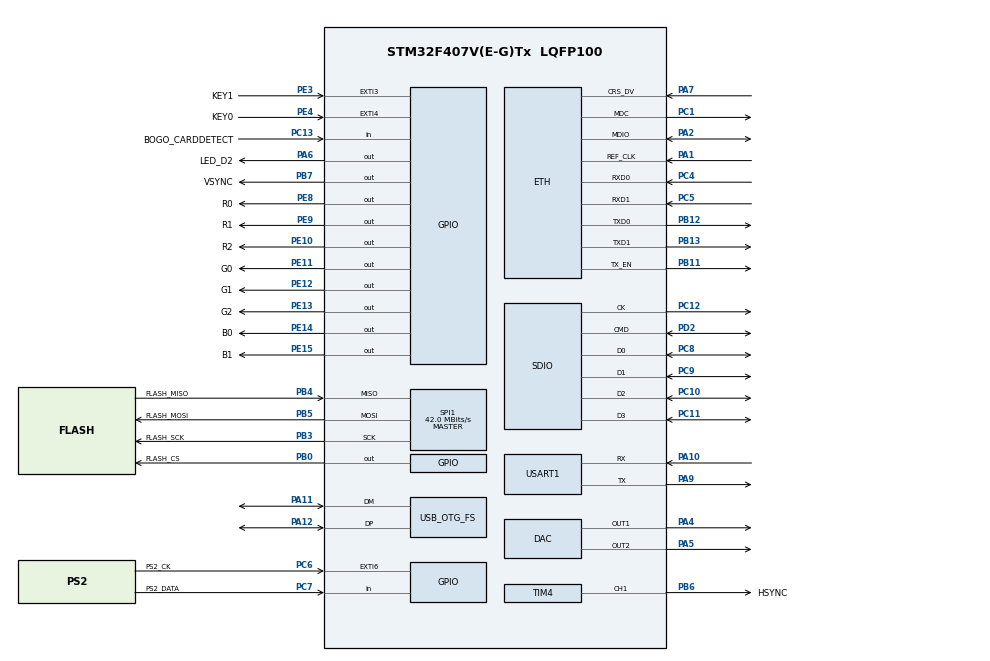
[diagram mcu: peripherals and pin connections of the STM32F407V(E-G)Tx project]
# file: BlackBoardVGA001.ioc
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DAC.DAC_OutputBuffer=DAC_OUTPUTBUFFER_DISABLE
DAC.DAC_OutputBuffer2=DAC_OUTPUTBUFFER_DISABLE
Dma.DAC1.2.Direction=DMA_MEMORY_TO_PERIPH
Dma.DAC1.2.FIFOMode=DMA_FIFOMODE_DISABLE
Dma.DAC1.2.Instance=DMA1_Stream5
Dma.DAC1.2.MemDataAlignment=DMA_MDATAALIGN_HALFWORD
Dma.DAC1.2.MemInc=DMA_MINC_ENABLE
Dma.DAC1.2.Mode=DMA_NORMAL
Dma.DAC1.2.PeriphDataAlignment=DMA_PDATAALIGN_HALFWORD
Dma.DAC1.2.PeriphInc=DMA_PINC_DISABLE
Dma.DAC1.2.Priority=DMA_PRIORITY_LOW
Dma.DAC2.3.Direction=DMA_MEMORY_TO_PERIPH
Dma.DAC2.3.FIFOMode=DMA_FIFOMODE_DISABLE
Dma.DAC2.3.Instance=DMA1_Stream6
Dma.DAC2.3.MemDataAlignment=DMA_MDATAALIGN_HALFWORD
Dma.DAC2.3.MemInc=DMA_MINC_ENABLE
Dma.DAC2.3.Mode=DMA_NORMAL
Dma.DAC2.3.PeriphDataAlignment=DMA_PDATAALIGN_HALFWORD
Dma.DAC2.3.PeriphInc=DMA_PINC_DISABLE
Dma.DAC2.3.Priority=DMA_PRIORITY_LOW
Dma.Request0=SDIO_RX
Dma.Request1=SDIO_TX
Dma.Request2=DAC1
Dma.Request3=DAC2
Dma.Request4=TIM1_UP
Dma.SDIO_RX.0.Direction=DMA_PERIPH_TO_MEMORY
Dma.SDIO_RX.0.FIFOMode=DMA_FIFOMODE_ENABLE
Dma.SDIO_RX.0.FIFOThreshold=DMA_FIFO_THRESHOLD_FULL
Dma.SDIO_RX.0.Instance=DMA2_Stream6
Dma.SDIO_RX.0.MemBurst=DMA_MBURST_INC4
Dma.SDIO_RX.0.MemDataAlignment=DMA_MDATAALIGN_WORD
Dma.SDIO_RX.0.MemInc=DMA_MINC_ENABLE
Dma.SDIO_RX.0.Mode=DMA_PFCTRL
Dma.SDIO_RX.0.PeriphBurst=DMA_PBURST_INC4
Dma.SDIO_RX.0.PeriphDataAlignment=DMA_PDATAALIGN_WORD
Dma.SDIO_RX.0.PeriphInc=DMA_PINC_DISABLE
Dma.SDIO_RX.0.Priority=DMA_PRIORITY_LOW
Dma.SDIO_TX.1.Direction=DMA_MEMORY_TO_PERIPH
Dma.SDIO_TX.1.FIFOMode=DMA_FIFOMODE_ENABLE
Dma.SDIO_TX.1.FIFOThreshold=DMA_FIFO_THRESHOLD_FULL
Dma.SDIO_TX.1.Instance=DMA2_Stream3
Dma.SDIO_TX.1.MemBurst=DMA_MBURST_INC4
Dma.SDIO_TX.1.MemDataAlignment=DMA_MDATAALIGN_WORD
Dma.SDIO_TX.1.MemInc=DMA_MINC_ENABLE
Dma.SDIO_TX.1.Mode=DMA_PFCTRL
Dma.SDIO_TX.1.PeriphBurst=DMA_PBURST_INC4
Dma.SDIO_TX.1.PeriphDataAlignment=DMA_PDATAALIGN_WORD
Dma.SDIO_TX.1.PeriphInc=DMA_PINC_DISABLE
Dma.SDIO_TX.1.Priority=DMA_PRIORITY_LOW
Dma.TIM1_UP.4.Direction=DMA_MEMORY_TO_PERIPH
Dma.TIM1_UP.4.FIFOMode=DMA_FIFOMODE_ENABLE
Dma.TIM1_UP.4.FIFOThreshold=DMA_FIFO_THRESHOLD_FULL
Dma.TIM1_UP.4.Instance=DMA2_Stream5
Dma.TIM1_UP.4.MemBurst=DMA_MBURST_SINGLE
Dma.TIM1_UP.4.MemDataAlignment=DMA_MDATAALIGN_WORD
Dma.TIM1_UP.4.MemInc=DMA_MINC_ENABLE
Dma.TIM1_UP.4.Mode=DMA_NORMAL
Dma.TIM1_UP.4.PeriphBurst=DMA_PBURST_SINGLE
Dma.TIM1_UP.4.PeriphDataAlignment=DMA_PDATAALIGN_BYTE
Dma.TIM1_UP.4.PeriphInc=DMA_PINC_DISABLE
Dma.TIM1_UP.4.Priority=DMA_PRIORITY_VERY_HIGH
ETH.MediaInterface=ETH_MEDIA_INTERFACE_RMII
FATFS.BSP.number=1
FATFS0.BSP.STBoard=false
FATFS0.BSP.api=Unknown
FATFS0.BSP.i2caddr=0
FATFS0.BSP.instance=PC13-ANTI_TAMP
FATFS0.BSP.ip=GPIO
FATFS0.BSP.mode=Input
FATFS0.BSP.name=Detect_SDIO
FATFS0.BSP.solution=PC13-ANTI_TAMP
FREERTOS.INCLUDE_uxTaskGetStackHighWaterMark=1
FREERTOS.INCLUDE_uxTaskGetStackHighWaterMark2=1
FREERTOS.INCLUDE_xTaskGetHandle=1
FREERTOS.Tasks01=defaultTask,0,128,StartDefaultTask,Default,NULL,Static,defaultTaskBuffer,defaultTaskControlBlock
FREERTOS.configCHECK_FOR_STACK_OVERFLOW=2
FREERTOS.configENABLE_FPU=1
FREERTOS.configTOTAL_HEAP_SIZE=16384
FREERTOS.configUSE_MALLOC_FAILED_HOOK=1
FREERTOS.configUSE_NEWLIB_REENTRANT=1
FREERTOS.configUSE_TRACE_FACILITY=1
FREERTOS.copyHeapFile=0
LWIP.LWIP_DNS=1
LWIP.Version=v2.1.2_Cube
Mcu.Family=STM32F4
Mcu.Name=STM32F407V(E-G)Tx
Mcu.Package=LQFP100
NVIC.DMA1_Stream5_IRQn=true\:5\:0\:false\:false\:true\:true\:false\:true
NVIC.DMA1_Stream6_IRQn=true\:5\:0\:false\:false\:true\:true\:false\:true
NVIC.DMA2_Stream3_IRQn=true\:5\:0\:false\:false\:true\:true\:false\:true
NVIC.DMA2_Stream5_IRQn=true\:5\:0\:false\:false\:true\:true\:false\:true
NVIC.DMA2_Stream6_IRQn=true\:5\:0\:false\:false\:true\:true\:false\:true
NVIC.ETH_IRQn=true\:5\:0\:false\:false\:true\:true\:false\:true
NVIC.EXTI3_IRQn=true\:5\:0\:false\:false\:true\:true\:true\:true
NVIC.EXTI4_IRQn=true\:5\:0\:false\:false\:true\:true\:true\:true
NVIC.EXTI9_5_IRQn=true\:5\:0\:false\:false\:true\:true\:true\:true
NVIC.FLASH_IRQn=true\:5\:0\:false\:false\:true\:true\:true\:true
NVIC.OTG_FS_IRQn=true\:5\:0\:false\:false\:true\:true\:false\:true
NVIC.PriorityGroup=NVIC_PRIORITYGROUP_4
NVIC.SDIO_IRQn=true\:5\:0\:false\:false\:true\:true\:true\:true
NVIC.SPI1_IRQn=true\:5\:0\:false\:false\:true\:true\:true\:true
NVIC.TIM4_IRQn=true\:0\:0\:true\:false\:true\:false\:true\:true
NVIC.TIM6_DAC_IRQn=true\:5\:0\:false\:false\:true\:true\:true\:true
NVIC.TIM8_BRK_TIM12_IRQn=true\:0\:0\:false\:false\:true\:false\:false\:true
NVIC.TimeBase=TIM8_BRK_TIM12_IRQn
NVIC.TimeBaseIP=TIM12
NVIC.USART1_IRQn=true\:5\:0\:false\:false\:true\:true\:true\:true
PA0-WKUP.Mode=SYS_WakeUp0
PA0-WKUP.Signal=SYS_WKUP
PA1.Mode=RMII
PA1.Signal=ETH_REF_CLK
PA10.Mode=Asynchronous
PA10.Signal=USART1_RX
PA11.Mode=Device_Only
PA11.Signal=USB_OTG_FS_DM
PA12.Mode=Device_Only
PA12.Signal=USB_OTG_FS_DP
PA13.Mode=Serial_Wire
PA13.Signal=SYS_JTMS-SWDIO
PA14.Mode=Serial_Wire
PA14.Signal=SYS_JTCK-SWCLK
PA2.Mode=RMII
PA2.Signal=ETH_MDIO
PA4.Signal=COMP_DAC1_group
PA5.Signal=COMP_DAC2_group
PA6.GPIO_Label=LED_D2
PA6.GPIO_ModeDefaultOutputPP=GPIO_MODE_OUTPUT_OD
PA6.PinState=GPIO_PIN_SET
PA6.Signal=GPIO_Output
PA7.Mode=RMII
PA7.Signal=ETH_CRS_DV
PA9.Mode=Asynchronous
PA9.Signal=USART1_TX
PB0.GPIO_Label=FLASH_CS
PB0.GPIO_Speed=GPIO_SPEED_FREQ_VERY_HIGH
PB0.PinState=GPIO_PIN_SET
PB0.Signal=GPIO_Output
PB11.Mode=RMII
PB11.Signal=ETH_TX_EN
PB12.Mode=RMII
PB12.Signal=ETH_TXD0
PB13.Mode=RMII
PB13.Signal=ETH_TXD1
PB3.GPIO_Label=FLASH_SCK
PB3.Mode=Full_Duplex_Master
PB3.Signal=SPI1_SCK
PB4.GPIO_Label=FLASH_MISO
PB4.Mode=Full_Duplex_Master
PB4.Signal=SPI1_MISO
PB5.GPIO_Label=FLASH_MOSI
PB5.Mode=Full_Duplex_Master
PB5.Signal=SPI1_MOSI
PB6.GPIO_Label=HSYNC
PB6.GPIO_Speed=GPIO_SPEED_FREQ_HIGH
PB6.Signal=S_TIM4_CH1
PB7.GPIO_Label=VSYNC
PB7.GPIO_Speed=GPIO_SPEED_FREQ_HIGH
PB7.Signal=GPIO_Output
PC1.Mode=RMII
PC1.Signal=ETH_MDC
PC10.GPIO_PuPd=GPIO_NOPULL
PC10.Mode=SD_4_bits_Wide_bus
PC10.Signal=SDIO_D2
PC11.GPIO_PuPd=GPIO_NOPULL
PC11.Mode=SD_4_bits_Wide_bus
PC11.Signal=SDIO_D3
PC12.Mode=SD_4_bits_Wide_bus
PC12.Signal=SDIO_CK
PC13-ANTI_TAMP.GPIO_Label=BOGO_CARDDETECT
PC13-ANTI_TAMP.GPIO_PuPd=GPIO_PULLDOWN
PC13-ANTI_TAMP.Signal=GPIO_Input
PC14-OSC32_IN.Mode=LSE-External-Oscillator
PC14-OSC32_IN.Signal=RCC_OSC32_IN
PC15-OSC32_OUT.Mode=LSE-External-Oscillator
PC15-OSC32_OUT.Signal=RCC_OSC32_OUT
PC4.Mode=RMII
PC4.Signal=ETH_RXD0
PC5.Mode=RMII
PC5.Signal=ETH_RXD1
PC6.GPIO_Label=PS2_CK
PC6.GPIO_ModeDefaultEXTI=GPIO_MODE_IT_FALLING
PC6.GPIO_PuPd=GPIO_PULLUP
PC6.Signal=GPXTI6
PC7.GPIO_Label=PS2_DATA
PC7.GPIO_PuPd=GPIO_PULLUP
PC7.Signal=GPIO_Input
PC8.GPIO_PuPd=GPIO_NOPULL
PC8.Mode=SD_4_bits_Wide_bus
PC8.Signal=SDIO_D0
PC9.GPIO_PuPd=GPIO_NOPULL
PC9.Mode=SD_4_bits_Wide_bus
PC9.Signal=SDIO_D1
PD2.GPIO_PuPd=GPIO_NOPULL
PD2.Mode=SD_4_bits_Wide_bus
PD2.Signal=SDIO_CMD
PE10.GPIO_Label=R2
PE10.GPIO_Speed=GPIO_SPEED_FREQ_VERY_HIGH
PE10.Signal=GPIO_Output
PE11.GPIO_Label=G0
PE11.GPIO_Speed=GPIO_SPEED_FREQ_VERY_HIGH
PE11.Signal=GPIO_Output
PE12.GPIO_Label=G1
PE12.GPIO_Speed=GPIO_SPEED_FREQ_VERY_HIGH
PE12.Signal=GPIO_Output
PE13.GPIO_Label=G2
PE13.GPIO_Speed=GPIO_SPEED_FREQ_VERY_HIGH
PE13.Signal=GPIO_Output
PE14.GPIO_Label=B0
PE14.GPIO_Speed=GPIO_SPEED_FREQ_VERY_HIGH
PE14.Signal=GPIO_Output
PE15.GPIO_Label=B1
PE15.GPIO_Speed=GPIO_SPEED_FREQ_VERY_HIGH
PE15.Signal=GPIO_Output
PE3.GPIO_Label=KEY1
PE3.GPIO_ModeDefaultEXTI=GPIO_MODE_IT_RISING_FALLING
PE3.GPIO_PuPd=GPIO_PULLUP
PE3.Signal=GPXTI3
PE4.GPIO_Label=KEY0
PE4.GPIO_ModeDefaultEXTI=GPIO_MODE_IT_RISING_FALLING
PE4.GPIO_PuPd=GPIO_PULLUP
PE4.Signal=GPXTI4
PE8.GPIO_Label=R0
PE8.GPIO_Speed=GPIO_SPEED_FREQ_VERY_HIGH
PE8.Signal=GPIO_Output
PE9.GPIO_Label=R1
PE9.GPIO_Speed=GPIO_SPEED_FREQ_VERY_HIGH
PE9.Signal=GPIO_Output
PH0-OSC_IN.Mode=HSE-External-Oscillator
PH0-OSC_IN.Signal=RCC_OSC_IN
PH1-OSC_OUT.Mode=HSE-External-Oscillator
PH1-OSC_OUT.Signal=RCC_OSC_OUT
ProjectManager.HeapSize=0x200
ProjectManager.StackSize=0x400
ProjectManager.TargetToolchain=SW4STM32
RCC.48MHZClocksFreq_Value=48000000
RCC.AHBFreq_Value=168000000
RCC.APB1CLKDivider=RCC_HCLK_DIV4
RCC.APB1Freq_Value=42000000
RCC.APB1TimFreq_Value=84000000
RCC.APB2CLKDivider=RCC_HCLK_DIV2
RCC.APB2Freq_Value=84000000
RCC.APB2TimFreq_Value=168000000
RCC.CortexFreq_Value=168000000
RCC.HCLKFreq_Value=168000000
RCC.HSE_VALUE=8000000
RCC.HSI_VALUE=16000000
RCC.PLLM=4
RCC.PLLN=168
RCC.PLLQ=7
RCC.RCC_RTC_Clock_Source=RCC_RTCCLKSOURCE_LSE
RCC.RCC_RTC_Clock_SourceVirtual=RCC_RTCCLKSOURCE_LSE
RCC.SYSCLKFreq_VALUE=168000000
RCC.SYSCLKSource=RCC_SYSCLKSOURCE_PLLCLK
RCC.VCOOutputFreq_Value=336000000
RTC.Date=1
RTC.Month=RTC_MONTH_JUNE
RTC.WeekDay=RTC_WEEKDAY_MONDAY
RTC.Year=20
SDIO.ClockBypass=SDIO_CLOCK_BYPASS_DISABLE
SDIO.ClockDiv=0
SH.COMP_DAC1_group.0=DAC_OUT1,DAC_OUT1
SH.COMP_DAC2_group.0=DAC_OUT2,DAC_OUT2
SH.S_TIM4_CH1.0=TIM4_CH1,PWM Generation1 CH1
SPI1.CalculateBaudRate=42.0 MBits/s
SPI1.Direction=SPI_DIRECTION_2LINES
SPI1.Mode=SPI_MODE_MASTER
SPI1.VirtualType=VM_MASTER
TIM1.Channel-PWM\ Generation1\ No\ Output=TIM_CHANNEL_1
TIM1.OCPolarity_1=TIM_OCPOLARITY_HIGH
TIM1.Period=3
TIM1.Pulse-PWM\ Generation1\ No\ Output=2
TIM4.Channel-Output\ Compare2\ No\ Output=TIM_CHANNEL_2
TIM4.Channel-Output\ Compare3\ No\ Output=TIM_CHANNEL_3
TIM4.Channel-PWM\ Generation1\ CH1=TIM_CHANNEL_1
TIM4.OC1Preload_PWM=DISABLE
TIM4.OCMode_2=TIM_OCMODE_ACTIVE
TIM4.OCPolarity_1=TIM_OCPOLARITY_HIGH
TIM4.Period=1055
TIM4.Prescaler=1
TIM4.Pulse-Output\ Compare2\ No\ Output=216
TIM4.Pulse-Output\ Compare3\ No\ Output=1016
TIM4.Pulse-PWM\ Generation1\ CH1=128
TIM4.TIM_MasterOutputTrigger=TIM_TRGO_OC2REF
TIM4.TIM_MasterSlaveMode=TIM_MASTERSLAVEMODE_DISABLE
USART1.VirtualMode=VM_ASYNC
USB_DEVICE.CLASS_NAME_FS=CDC
USB_DEVICE.VirtualMode-CDC_FS=Cdc
USB_DEVICE.VirtualModeFS=Cdc_FS
USB_OTG_FS.VirtualMode=Device_Only
VP_FATFS_VS_SDIO.Mode=SDIO
VP_FREERTOS_VS_CMSIS_V1.Mode=CMSIS_V1
VP_LWIP_VS_Enabled.Mode=Enabled
VP_RTC_VS_RTC_Activate.Mode=RTC_Enabled
VP_RTC_VS_RTC_Calendar.Mode=RTC_Calendar
VP_SYS_VS_tim12.Mode=TIM12
VP_TIM1_VS_ClockSourceINT.Mode=Internal
VP_TIM1_VS_ClockSourceITR.Mode=TriggerSource_ITR3
VP_TIM1_VS_ControllerModeTrigger.Mode=Trigger Mode
VP_TIM1_VS_no_output1.Mode=PWM Generation1 No Output
VP_TIM4_VS_ClockSourceINT.Mode=Internal
VP_TIM4_VS_no_output2.Mode=Output Compare2 No Output
VP_TIM4_VS_no_output3.Mode=Output Compare3 No Output
VP_USB_DEVICE_VS_USB_DEVICE_CDC_FS.Mode=CDC_FS
board=custom

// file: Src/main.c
/* USER CODE BEGIN Header */
/**
  ******************************************************************************
  * @file           : main.c
  * @brief          : Main program body
  ******************************************************************************
  * @attention
  *
  * <h2><center>&copy; Copyright (c) 2020 STMicroelectronics.
  * All rights reserved.</center></h2>
  *
  * This software component is licensed by ST under BSD 3-Clause license,
  * the "License"; You may not use this file except in compliance with the
  * License. You may obtain a copy of the License at:
  *                        opensource.org/licenses/BSD-3-Clause
  *
  ******************************************************************************
  */
/* USER CODE END Header */

#include "main.h"
#include "cmsis_os.h"
#include "fatfs.h"
#include "lwip.h"
#include "usb_device.h"

/* USER CODE BEGIN Includes */

#if HAVE_USBCDC
#include "usbd_cdc.h"	//just for the XXX_USBCDC_PresenceHack()
#endif
#include "system_interfaces.h"
#include "serial_devices.h"
#include "util_circbuff2.h"

#include "lamps.h"
#include "task_notification_bits.h"

#include "task_monitor.h"

#include "video.h"

//get the debug cycle counter as a high-resolution clock
uint32_t inline getCyCnt() { return DWT->CYCCNT; }

#ifndef COUNTOF
#define COUNTOF(arr) (sizeof(arr)/sizeof(arr[0]))
#endif

#if ! HAVE_UART1 && ! HAVE_USBCDC
#error You must set at least one of HAVE_UART1 HAVE_USBCDC to 1 in project settings
#endif

//This controls whether we use the FreeRTOS heap implementation to also provide
//the libc malloc() and friends.
#define USE_FREERTOS_HEAP_IMPL 1

//resource usage statistics collected in default task for production tuning
#ifdef DEBUG
volatile size_t g_nHeapFree;
volatile size_t g_nMinEverHeapFree;
#if HAVE_UART1
volatile int g_nMaxUART1TxQueue;
volatile int g_nMaxUART1RxQueue;
#endif
#if HAVE_USBCDC
volatile int g_nMaxCDCTxQueue;
volatile int g_nMaxCDCRxQueue;
#endif
volatile int g_nMinStackFreeDefault;
volatile int g_nMinStackFreeMonitor;

//alas, the LWIP and ETH discard the thread id's they create
//\Middlewares\Third_Party\LwIP\src\api\tcpip.c:617
//\src\ethernetif.c:273 (this one is in a USER block, so we can edit)
//we will use carnal knowledge of their thread names, and the xTaskGetHandle api
TaskHandle_t g_thTCP;
TaskHandle_t g_thETH;
volatile int g_nMinStackFreeTCP;
volatile int g_nMinStackFreeETH;

//XXX others
#endif

#if USE_FREERTOS_HEAP_IMPL

#if configAPPLICATION_ALLOCATED_HEAP
//we define our heap (to be used by FreeRTOS heap_4.c implementation) to be
//exactly where we want it to be.
__attribute__((aligned(8)))
uint8_t ucHeap[ configTOTAL_HEAP_SIZE ];
#endif
//we implemented a 'realloc' for a heap_4 derived implementation
extern void* pvPortRealloc( void* pvOrig, size_t xWantedSize );
//we implemented a 'heapwalk' function
typedef int (*CBK_HEAPWALK) ( void* pblk, uint32_t nBlkSize, int bIsFree, void* pinst );
extern int vPortHeapWalk ( CBK_HEAPWALK pfnWalk, void* pinst );

//'wrapped functions' for library interpositioning
//you must specify these gcc (linker-directed) options to cause the wrappers'
//delights to be generated:

// -Wl,--wrap,malloc -Wl,--wrap,free -Wl,--wrap,realloc -Wl,--wrap,calloc -Wl,--wrap,_malloc_r -Wl,--wrap,_free_r -Wl,--wrap,_realloc_r -Wl,--wrap,_calloc_r

//hmm; can I declare these 'inline' and save a little code and stack?
void* __wrap_malloc ( size_t size ) { return pvPortMalloc ( size ); }
void __wrap_free ( void* pv ) { vPortFree ( pv ); }
void* __wrap_realloc ( void* pv, size_t size ) { return pvPortRealloc ( pv, size ); }

void* __wrap__malloc_r ( struct _reent* r, size_t size ) { return pvPortMalloc ( size ); }
void __wrap__free_r ( struct _reent* r, void* pv ) { vPortFree ( pv ); }
void* __wrap__realloc_r ( struct _reent* r, void* pv, size_t size ) { return pvPortRealloc ( pv, size ); }

#endif

/* USER CODE END Includes */

/* USER CODE BEGIN PM */

//I wanted the task stuff (especially FreeRTOS stack) to be in CCM, freeing the
//main memory for things that might need to interact with peripherals;
//especially DMA.

//The other stuff doesn't /have/ to be there, but might as well get it out of
//main SRAM since the CCRAM is otherwise going unused.

//XXX generated code hack; we put things right where we want them to be, above.
//If you get some linker errors after you modify the CubeMX project, it might
//be that it added stuff during generation, below, and that is conditioned-out.
//So just copy whatever it is above.
#if 1

//DMA 'handles' cannot be in CCM because the DMA controller will access some members and CCM is inaccessible to the DMA controllers.
SD_HandleTypeDef hsd;// __ccram;
DMA_HandleTypeDef hdma_sdio_rx;// __ccram;
DMA_HandleTypeDef hdma_sdio_tx;// __ccram;

osThreadId defaultTaskHandle __ccram;
uint32_t defaultTaskBuffer[ 128 ] __ccram;
osStaticThreadDef_t defaultTaskControlBlock __ccram;

#else
/* USER CODE END PM */

SD_HandleTypeDef hsd;
DMA_HandleTypeDef hdma_sdio_rx;
DMA_HandleTypeDef hdma_sdio_tx;

osThreadId defaultTaskHandle;
uint32_t defaultTaskBuffer[ 128 ];
osStaticThreadDef_t defaultTaskControlBlock;
/* USER CODE BEGIN PV */
//XXX end generate code hack
#endif

/* USER CODE END PV */

void SystemClock_Config(void);
static void MX_GPIO_Init(void);
static void MX_DMA_Init(void);
static void MX_RTC_Init(void);
static void MX_SDIO_SD_Init(void);
static void MX_SPI1_Init(void);
static void MX_USART1_UART_Init(void);
static void MX_DAC_Init(void);
static void MX_TIM4_Init(void);
static void MX_TIM1_Init(void);
void StartDefaultTask(void const * argument);

/* USER CODE BEGIN 0 */

//hack:  the CubeMX generated LL code for SystemClock_Config /always/ resets
//the backup domain, thereby clearing the RTC amongst other things.  It is not
//easy to fix because there are no USER tags therein, we we neutralize those
//APIs altogether.
#define LL_RCC_ForceBackupDomainReset(a)do{}while(0)
#define LL_RCC_ReleaseBackupDomainReset(a)do{}while(0)

/* USER CODE END 0 */

int main(void)
{
  /* USER CODE BEGIN 1 */
	//enable the core debug cycle counter to be used as a precision timer
	CoreDebug->DEMCR |= CoreDebug_DEMCR_TRCENA_Msk;
	DWT->CYCCNT = 0;
	DWT->CTRL |= DWT_CTRL_CYCCNTENA_Msk;

	//set up that the video-related timers will stop when debugging
	__HAL_DBGMCU_FREEZE_TIM4();
	__HAL_DBGMCU_FREEZE_TIM1();

	//do a dummy alloc to cause the heap to be init'ed and so the memory stats as well
	vPortFree ( pvPortMalloc ( 0 ) );

  /* USER CODE END 1 */

  /* MCU Configuration--------------------------------------------------------*/

  /* Reset of all peripherals, Initializes the Flash interface and the Systick. */
  HAL_Init();

  /* USER CODE BEGIN Init */

#if HAVE_USBCDC
	//if you get a linker fail on the following, it is because some manual
	//changes to:
	//  .\Middlewares\ST\STM32_USB_Device_Library\Class\CDC\Inc\usbd_cdc.h
	//  .\Middlewares\ST\STM32_USB_Device_Library\Class\CDC\Src\usbd_cdc.c
	//  .\Src\usbd_cdc_if.c
	//must be applied.  There are backups of those files to help with that.
	//This has to be done manually, because the changes are in tool generated
	//code that gets overwritten when you re-run STM32CubeMX.  The nature of
	//those changes are such that when they are overwritten, you will still
	//be able to build but stuff won't work at runtime.  This hack will cause
	//the build to fail if you forget to merge those changes back on, thus
	//prompting you to do so.
	//There is a #fixups/fixup.bat to help with this.
	//Sorry for the inconvenience, but I don't think there is any better way
	//of making it obvious that this chore simply must be done.
	XXX_USBCDC_PresenceHack();	//this does nothing real; do not delete
#endif

	//if there are any __ccram objects that need static initialization, you'll
	//need to do that here because the startup code does not init them out-of-
	//box like it does with the .data section (alternatively, you can modify
	//the startup_stm32f407xx.s to do this, along with some linker script
	//shenanigans to set up the needed symbols).
	defaultTaskHandle = NULL;
	g_thMonitor = NULL;
	g_pMonitorIOIf = NULL;

  /* USER CODE END Init */

  /* Configure the system clock */
  SystemClock_Config();

  /* USER CODE BEGIN SysInit */

	//turn on the low power regulator so the backup sram will indeed be battery backed
	LL_PWR_EnableBkUpAccess();	//ensure access to the backup domain, if not already

	{	//ensure the power clock is on, if not already
	SET_BIT(RCC->APB1ENR, RCC_APB1ENR_PWREN);
	volatile uint32_t n = READ_BIT(RCC->APB1ENR, RCC_APB1ENR_PWREN);	//Delay after an RCC peripheral clock enabling
	(void)n;
	}

	LL_PWR_EnableBkUpRegulator();	//turn on the backup regulator...
	while ( !LL_PWR_IsActiveFlag_BRR() ) {}	//... and wait for stabilization XXX timeout?
	//leave access to the backup domain active so we can freely fiddle with rtc, etc

	{	//enable the backup sram clock, and just leave it running so we can access freely
	SET_BIT(RCC->AHB1ENR, RCC_AHB1ENR_BKPSRAMEN);
	volatile uint32_t n = READ_BIT(RCC->AHB1ENR, RCC_AHB1ENR_BKPSRAMEN);	//Delay after an RCC peripheral clock enabling
	(void)n;
	}

  /* USER CODE END SysInit */

  /* Initialize all configured peripherals */
  MX_GPIO_Init();
  MX_DMA_Init();
  MX_RTC_Init();
  MX_SDIO_SD_Init();
  MX_SPI1_Init();
  MX_USART1_UART_Init();
  MX_FATFS_Init();
  MX_DAC_Init();
  MX_TIM4_Init();
  MX_TIM1_Init();

  /* Create the thread(s) */
  /* definition and creation of defaultTask */
  osThreadStaticDef(defaultTask, StartDefaultTask, osPriorityNormal, 0, 128, defaultTaskBuffer, &defaultTaskControlBlock);
  defaultTaskHandle = osThreadCreate(osThread(defaultTask), NULL);

  /* Start scheduler */
  osKernelStart();

  /* We should never get here as control is now taken by the scheduler */
  /* Infinite loop */
  while (1)
  {

  }
}

void SystemClock_Config(void)
{
  LL_FLASH_SetLatency(LL_FLASH_LATENCY_5);

  if(LL_FLASH_GetLatency() != LL_FLASH_LATENCY_5)
  {
  Error_Handler();
  }
  LL_PWR_SetRegulVoltageScaling(LL_PWR_REGU_VOLTAGE_SCALE1);
  LL_RCC_HSE_Enable();

   /* Wait till HSE is ready */
  while(LL_RCC_HSE_IsReady() != 1)
  {

  }
  LL_PWR_EnableBkUpAccess();
  LL_RCC_ForceBackupDomainReset();
  LL_RCC_ReleaseBackupDomainReset();
  LL_RCC_LSE_Enable();

   /* Wait till LSE is ready */
  while(LL_RCC_LSE_IsReady() != 1)
  {

  }
  LL_RCC_SetRTCClockSource(LL_RCC_RTC_CLKSOURCE_LSE);
  LL_RCC_EnableRTC();
  LL_RCC_PLL_ConfigDomain_SYS(LL_RCC_PLLSOURCE_HSE, LL_RCC_PLLM_DIV_4, 168, LL_RCC_PLLP_DIV_2);
  LL_RCC_PLL_ConfigDomain_48M(LL_RCC_PLLSOURCE_HSE, LL_RCC_PLLM_DIV_4, 168, LL_RCC_PLLQ_DIV_7);
  LL_RCC_PLL_Enable();

   /* Wait till PLL is ready */
  while(LL_RCC_PLL_IsReady() != 1)
  {

  }
  LL_RCC_SetAHBPrescaler(LL_RCC_SYSCLK_DIV_1);
  LL_RCC_SetAPB1Prescaler(LL_RCC_APB1_DIV_4);
  LL_RCC_SetAPB2Prescaler(LL_RCC_APB2_DIV_2);
  LL_RCC_SetSysClkSource(LL_RCC_SYS_CLKSOURCE_PLL);

   /* Wait till System clock is ready */
  while(LL_RCC_GetSysClkSource() != LL_RCC_SYS_CLKSOURCE_STATUS_PLL)
  {

  }
  LL_SetSystemCoreClock(168000000);

   /* Update the time base */
  if (HAL_InitTick (TICK_INT_PRIORITY) != HAL_OK)
  {
    Error_Handler();
  };
}

static void MX_DAC_Init(void)
{

  LL_DAC_InitTypeDef DAC_InitStruct = {0};

  LL_GPIO_InitTypeDef GPIO_InitStruct = {0};

  /* Peripheral clock enable */
  LL_APB1_GRP1_EnableClock(LL_APB1_GRP1_PERIPH_DAC1);

  LL_AHB1_GRP1_EnableClock(LL_AHB1_GRP1_PERIPH_GPIOA);
  /**DAC GPIO Configuration
  PA4   ------> DAC_OUT1
  PA5   ------> DAC_OUT2
  */
  GPIO_InitStruct.Pin = LL_GPIO_PIN_4|LL_GPIO_PIN_5;
  GPIO_InitStruct.Mode = LL_GPIO_MODE_ANALOG;
  GPIO_InitStruct.Pull = LL_GPIO_PULL_NO;
  LL_GPIO_Init(GPIOA, &GPIO_InitStruct);

  /* DAC DMA Init */

  /* DAC1 Init */
  LL_DMA_SetChannelSelection(DMA1, LL_DMA_STREAM_5, LL_DMA_CHANNEL_7);

  LL_DMA_SetDataTransferDirection(DMA1, LL_DMA_STREAM_5, LL_DMA_DIRECTION_MEMORY_TO_PERIPH);

  LL_DMA_SetStreamPriorityLevel(DMA1, LL_DMA_STREAM_5, LL_DMA_PRIORITY_LOW);

  LL_DMA_SetMode(DMA1, LL_DMA_STREAM_5, LL_DMA_MODE_NORMAL);

  LL_DMA_SetPeriphIncMode(DMA1, LL_DMA_STREAM_5, LL_DMA_PERIPH_NOINCREMENT);

  LL_DMA_SetMemoryIncMode(DMA1, LL_DMA_STREAM_5, LL_DMA_MEMORY_INCREMENT);

  LL_DMA_SetPeriphSize(DMA1, LL_DMA_STREAM_5, LL_DMA_PDATAALIGN_HALFWORD);

  LL_DMA_SetMemorySize(DMA1, LL_DMA_STREAM_5, LL_DMA_MDATAALIGN_HALFWORD);

  LL_DMA_DisableFifoMode(DMA1, LL_DMA_STREAM_5);

  /* DAC2 Init */
  LL_DMA_SetChannelSelection(DMA1, LL_DMA_STREAM_6, LL_DMA_CHANNEL_7);

  LL_DMA_SetDataTransferDirection(DMA1, LL_DMA_STREAM_6, LL_DMA_DIRECTION_MEMORY_TO_PERIPH);

  LL_DMA_SetStreamPriorityLevel(DMA1, LL_DMA_STREAM_6, LL_DMA_PRIORITY_LOW);

  LL_DMA_SetMode(DMA1, LL_DMA_STREAM_6, LL_DMA_MODE_NORMAL);

  LL_DMA_SetPeriphIncMode(DMA1, LL_DMA_STREAM_6, LL_DMA_PERIPH_NOINCREMENT);

  LL_DMA_SetMemoryIncMode(DMA1, LL_DMA_STREAM_6, LL_DMA_MEMORY_INCREMENT);

  LL_DMA_SetPeriphSize(DMA1, LL_DMA_STREAM_6, LL_DMA_PDATAALIGN_HALFWORD);

  LL_DMA_SetMemorySize(DMA1, LL_DMA_STREAM_6, LL_DMA_MDATAALIGN_HALFWORD);

  LL_DMA_DisableFifoMode(DMA1, LL_DMA_STREAM_6);

  /* DAC interrupt Init */
  NVIC_SetPriority(TIM6_DAC_IRQn, NVIC_EncodePriority(NVIC_GetPriorityGrouping(),5, 0));
  NVIC_EnableIRQ(TIM6_DAC_IRQn);

  /** DAC channel OUT1 config
  */
  DAC_InitStruct.TriggerSource = LL_DAC_TRIG_SOFTWARE;
  DAC_InitStruct.WaveAutoGeneration = LL_DAC_WAVE_AUTO_GENERATION_NONE;
  DAC_InitStruct.OutputBuffer = LL_DAC_OUTPUT_BUFFER_DISABLE;
  LL_DAC_Init(DAC, LL_DAC_CHANNEL_1, &DAC_InitStruct);
  /** DAC channel OUT2 config
  */
  LL_DAC_Init(DAC, LL_DAC_CHANNEL_2, &DAC_InitStruct);

}

static void MX_RTC_Init(void)
{

  /* USER CODE BEGIN RTC_Init 0 */
	//I don't know why I have to do this, but if I don't the following Init
	//and SetXXX functions will fail, seemingly randomly.
	__HAL_RCC_RTC_ENABLE();
  /* USER CODE END RTC_Init 0 */

  LL_RTC_InitTypeDef RTC_InitStruct = {0};
  LL_RTC_TimeTypeDef RTC_TimeStruct = {0};
  LL_RTC_DateTypeDef RTC_DateStruct = {0};

  /* Peripheral clock enable */
  LL_RCC_EnableRTC();

  /* USER CODE BEGIN RTC_Init 1 */

	//The generated code uses a backup register to determine if the clock has
	//ever been set, but we don't really need to do that since we have a flag
	//on this chip for that purpose.

	//is it really necessary to do this each time?
	RTC_InitStruct.HourFormat = LL_RTC_HOURFORMAT_24HOUR;
	RTC_InitStruct.AsynchPrescaler = 127;
	RTC_InitStruct.SynchPrescaler = 255;
	LL_RTC_Init(RTC, &RTC_InitStruct);
	LL_RTC_SetAsynchPrescaler(RTC, 127);
	LL_RTC_SetSynchPrescaler(RTC, 255);

	//if we've already initted the clock, do not reset the time/date
	if ( RTC->ISR & RTC_ISR_INITS )
	{
		LL_RTC_DisableWriteProtection(RTC);
	}
	else
	{
		//explicitly setting the datetime to a default value
		RTC_TimeStruct.Hours = 0;
		RTC_TimeStruct.Minutes = 0;
		RTC_TimeStruct.Seconds = 0;
		LL_RTC_TIME_Init(RTC, LL_RTC_FORMAT_BCD, &RTC_TimeStruct);
		RTC_DateStruct.WeekDay = LL_RTC_WEEKDAY_MONDAY;
		RTC_DateStruct.Day = 1;
		RTC_DateStruct.Month = LL_RTC_MONTH_JUNE;
		RTC_DateStruct.Year = 20;
		LL_RTC_DATE_Init(RTC, LL_RTC_FORMAT_BCD, &RTC_DateStruct);
	}

#if 0	//goodbye goofy code
  /* USER CODE END RTC_Init 1 */
  /** Initialize RTC and set the Time and Date
  */
  RTC_InitStruct.HourFormat = LL_RTC_HOURFORMAT_24HOUR;
  RTC_InitStruct.AsynchPrescaler = 127;
  RTC_InitStruct.SynchPrescaler = 255;
  LL_RTC_Init(RTC, &RTC_InitStruct);
  LL_RTC_SetAsynchPrescaler(RTC, 127);
  LL_RTC_SetSynchPrescaler(RTC, 255);
  /** Initialize RTC and set the Time and Date
  */
  if(LL_RTC_BAK_GetRegister(RTC, LL_RTC_BKP_DR0) != 0x32F2){

  RTC_TimeStruct.Hours = 0;
  RTC_TimeStruct.Minutes = 0;
  RTC_TimeStruct.Seconds = 0;
  LL_RTC_TIME_Init(RTC, LL_RTC_FORMAT_BCD, &RTC_TimeStruct);
  RTC_DateStruct.WeekDay = LL_RTC_WEEKDAY_MONDAY;
  RTC_DateStruct.Month = LL_RTC_MONTH_JUNE;
  RTC_DateStruct.Year = 20;
  LL_RTC_DATE_Init(RTC, LL_RTC_FORMAT_BCD, &RTC_DateStruct);
    LL_RTC_BAK_SetRegister(RTC,LL_RTC_BKP_DR0,0x32F2);
  }
  /* USER CODE BEGIN RTC_Init 2 */
#endif

  /* USER CODE END RTC_Init 2 */

}

static void MX_SDIO_SD_Init(void)
{

  hsd.Instance = SDIO;
  hsd.Init.ClockEdge = SDIO_CLOCK_EDGE_RISING;
  hsd.Init.ClockBypass = SDIO_CLOCK_BYPASS_DISABLE;
  hsd.Init.ClockPowerSave = SDIO_CLOCK_POWER_SAVE_DISABLE;
  hsd.Init.BusWide = SDIO_BUS_WIDE_1B;
  hsd.Init.HardwareFlowControl = SDIO_HARDWARE_FLOW_CONTROL_DISABLE;
  hsd.Init.ClockDiv = 0;

}

static void MX_SPI1_Init(void)
{

  LL_SPI_InitTypeDef SPI_InitStruct = {0};

  LL_GPIO_InitTypeDef GPIO_InitStruct = {0};

  /* Peripheral clock enable */
  LL_APB2_GRP1_EnableClock(LL_APB2_GRP1_PERIPH_SPI1);

  LL_AHB1_GRP1_EnableClock(LL_AHB1_GRP1_PERIPH_GPIOB);
  /**SPI1 GPIO Configuration
  PB3   ------> SPI1_SCK
  PB4   ------> SPI1_MISO
  PB5   ------> SPI1_MOSI
  */
  GPIO_InitStruct.Pin = FLASH_SCK_Pin|FLASH_MISO_Pin|FLASH_MOSI_Pin;
  GPIO_InitStruct.Mode = LL_GPIO_MODE_ALTERNATE;
  GPIO_InitStruct.Speed = LL_GPIO_SPEED_FREQ_VERY_HIGH;
  GPIO_InitStruct.OutputType = LL_GPIO_OUTPUT_PUSHPULL;
  GPIO_InitStruct.Pull = LL_GPIO_PULL_NO;
  GPIO_InitStruct.Alternate = LL_GPIO_AF_5;
  LL_GPIO_Init(GPIOB, &GPIO_InitStruct);

  /* SPI1 interrupt Init */
  NVIC_SetPriority(SPI1_IRQn, NVIC_EncodePriority(NVIC_GetPriorityGrouping(),5, 0));
  NVIC_EnableIRQ(SPI1_IRQn);

  /* SPI1 parameter configuration*/
  SPI_InitStruct.TransferDirection = LL_SPI_FULL_DUPLEX;
  SPI_InitStruct.Mode = LL_SPI_MODE_MASTER;
  SPI_InitStruct.DataWidth = LL_SPI_DATAWIDTH_8BIT;
  SPI_InitStruct.ClockPolarity = LL_SPI_POLARITY_LOW;
  SPI_InitStruct.ClockPhase = LL_SPI_PHASE_1EDGE;
  SPI_InitStruct.NSS = LL_SPI_NSS_SOFT;
  SPI_InitStruct.BaudRate = LL_SPI_BAUDRATEPRESCALER_DIV2;
  SPI_InitStruct.BitOrder = LL_SPI_MSB_FIRST;
  SPI_InitStruct.CRCCalculation = LL_SPI_CRCCALCULATION_DISABLE;
  SPI_InitStruct.CRCPoly = 10;
  LL_SPI_Init(SPI1, &SPI_InitStruct);
  LL_SPI_SetStandard(SPI1, LL_SPI_PROTOCOL_MOTOROLA);

}

static void MX_TIM1_Init(void)
{

  LL_TIM_InitTypeDef TIM_InitStruct = {0};
  LL_TIM_OC_InitTypeDef TIM_OC_InitStruct = {0};
  LL_TIM_BDTR_InitTypeDef TIM_BDTRInitStruct = {0};

  /* Peripheral clock enable */
  LL_APB2_GRP1_EnableClock(LL_APB2_GRP1_PERIPH_TIM1);

  /* TIM1 DMA Init */

  /* TIM1_UP Init */
  LL_DMA_SetChannelSelection(DMA2, LL_DMA_STREAM_5, LL_DMA_CHANNEL_6);

  LL_DMA_SetDataTransferDirection(DMA2, LL_DMA_STREAM_5, LL_DMA_DIRECTION_MEMORY_TO_PERIPH);

  LL_DMA_SetStreamPriorityLevel(DMA2, LL_DMA_STREAM_5, LL_DMA_PRIORITY_VERYHIGH);

  LL_DMA_SetMode(DMA2, LL_DMA_STREAM_5, LL_DMA_MODE_NORMAL);

  LL_DMA_SetPeriphIncMode(DMA2, LL_DMA_STREAM_5, LL_DMA_PERIPH_NOINCREMENT);

  LL_DMA_SetMemoryIncMode(DMA2, LL_DMA_STREAM_5, LL_DMA_MEMORY_INCREMENT);

  LL_DMA_SetPeriphSize(DMA2, LL_DMA_STREAM_5, LL_DMA_PDATAALIGN_BYTE);

  LL_DMA_SetMemorySize(DMA2, LL_DMA_STREAM_5, LL_DMA_MDATAALIGN_WORD);

  LL_DMA_EnableFifoMode(DMA2, LL_DMA_STREAM_5);

  LL_DMA_SetFIFOThreshold(DMA2, LL_DMA_STREAM_5, LL_DMA_FIFOTHRESHOLD_FULL);

  LL_DMA_SetMemoryBurstxfer(DMA2, LL_DMA_STREAM_5, LL_DMA_MBURST_SINGLE);

  LL_DMA_SetPeriphBurstxfer(DMA2, LL_DMA_STREAM_5, LL_DMA_PBURST_SINGLE);

  TIM_InitStruct.Prescaler = 0;
  TIM_InitStruct.CounterMode = LL_TIM_COUNTERMODE_UP;
  TIM_InitStruct.Autoreload = 3;
  TIM_InitStruct.ClockDivision = LL_TIM_CLOCKDIVISION_DIV1;
  TIM_InitStruct.RepetitionCounter = 0;
  LL_TIM_Init(TIM1, &TIM_InitStruct);
  LL_TIM_DisableARRPreload(TIM1);
  LL_TIM_SetClockSource(TIM1, LL_TIM_CLOCKSOURCE_INTERNAL);
  LL_TIM_OC_EnablePreload(TIM1, LL_TIM_CHANNEL_CH1);
  TIM_OC_InitStruct.OCMode = LL_TIM_OCMODE_PWM1;
  TIM_OC_InitStruct.OCState = LL_TIM_OCSTATE_DISABLE;
  TIM_OC_InitStruct.OCNState = LL_TIM_OCSTATE_DISABLE;
  TIM_OC_InitStruct.CompareValue = 2;
  TIM_OC_InitStruct.OCPolarity = LL_TIM_OCPOLARITY_HIGH;
  TIM_OC_InitStruct.OCNPolarity = LL_TIM_OCPOLARITY_HIGH;
  TIM_OC_InitStruct.OCIdleState = LL_TIM_OCIDLESTATE_LOW;
  TIM_OC_InitStruct.OCNIdleState = LL_TIM_OCIDLESTATE_LOW;
  LL_TIM_OC_Init(TIM1, LL_TIM_CHANNEL_CH1, &TIM_OC_InitStruct);
  LL_TIM_OC_DisableFast(TIM1, LL_TIM_CHANNEL_CH1);
  LL_TIM_SetTriggerInput(TIM1, LL_TIM_TS_ITR3);
  LL_TIM_SetSlaveMode(TIM1, LL_TIM_SLAVEMODE_TRIGGER);
  LL_TIM_DisableIT_TRIG(TIM1);
  LL_TIM_DisableDMAReq_TRIG(TIM1);
  LL_TIM_SetTriggerOutput(TIM1, LL_TIM_TRGO_RESET);
  LL_TIM_DisableMasterSlaveMode(TIM1);
  TIM_BDTRInitStruct.OSSRState = LL_TIM_OSSR_DISABLE;
  TIM_BDTRInitStruct.OSSIState = LL_TIM_OSSI_DISABLE;
  TIM_BDTRInitStruct.LockLevel = LL_TIM_LOCKLEVEL_OFF;
  TIM_BDTRInitStruct.DeadTime = 0;
  TIM_BDTRInitStruct.BreakState = LL_TIM_BREAK_DISABLE;
  TIM_BDTRInitStruct.BreakPolarity = LL_TIM_BREAK_POLARITY_HIGH;
  TIM_BDTRInitStruct.AutomaticOutput = LL_TIM_AUTOMATICOUTPUT_DISABLE;
  LL_TIM_BDTR_Init(TIM1, &TIM_BDTRInitStruct);

}

static void MX_TIM4_Init(void)
{

  LL_TIM_InitTypeDef TIM_InitStruct = {0};
  LL_TIM_OC_InitTypeDef TIM_OC_InitStruct = {0};

  LL_GPIO_InitTypeDef GPIO_InitStruct = {0};

  /* Peripheral clock enable */
  LL_APB1_GRP1_EnableClock(LL_APB1_GRP1_PERIPH_TIM4);

  /* TIM4 interrupt Init */
  NVIC_SetPriority(TIM4_IRQn, NVIC_EncodePriority(NVIC_GetPriorityGrouping(),0, 0));
  NVIC_EnableIRQ(TIM4_IRQn);

  TIM_InitStruct.Prescaler = 1;
  TIM_InitStruct.CounterMode = LL_TIM_COUNTERMODE_UP;
  TIM_InitStruct.Autoreload = 1055;
  TIM_InitStruct.ClockDivision = LL_TIM_CLOCKDIVISION_DIV1;
  LL_TIM_Init(TIM4, &TIM_InitStruct);
  LL_TIM_DisableARRPreload(TIM4);
  LL_TIM_SetClockSource(TIM4, LL_TIM_CLOCKSOURCE_INTERNAL);
  LL_TIM_OC_EnablePreload(TIM4, LL_TIM_CHANNEL_CH1);
  TIM_OC_InitStruct.OCMode = LL_TIM_OCMODE_PWM1;
  TIM_OC_InitStruct.OCState = LL_TIM_OCSTATE_DISABLE;
  TIM_OC_InitStruct.OCNState = LL_TIM_OCSTATE_DISABLE;
  TIM_OC_InitStruct.CompareValue = 128;
  TIM_OC_InitStruct.OCPolarity = LL_TIM_OCPOLARITY_HIGH;
  LL_TIM_OC_Init(TIM4, LL_TIM_CHANNEL_CH1, &TIM_OC_InitStruct);
  LL_TIM_OC_DisableFast(TIM4, LL_TIM_CHANNEL_CH1);
  TIM_OC_InitStruct.OCMode = LL_TIM_OCMODE_ACTIVE;
  TIM_OC_InitStruct.OCState = LL_TIM_OCSTATE_DISABLE;
  TIM_OC_InitStruct.OCNState = LL_TIM_OCSTATE_DISABLE;
  TIM_OC_InitStruct.CompareValue = 216;
  LL_TIM_OC_Init(TIM4, LL_TIM_CHANNEL_CH2, &TIM_OC_InitStruct);
  LL_TIM_OC_DisableFast(TIM4, LL_TIM_CHANNEL_CH2);
  TIM_OC_InitStruct.OCMode = LL_TIM_OCMODE_FROZEN;
  TIM_OC_InitStruct.OCState = LL_TIM_OCSTATE_DISABLE;
  TIM_OC_InitStruct.OCNState = LL_TIM_OCSTATE_DISABLE;
  TIM_OC_InitStruct.CompareValue = 1016;
  LL_TIM_OC_Init(TIM4, LL_TIM_CHANNEL_CH3, &TIM_OC_InitStruct);
  LL_TIM_OC_DisableFast(TIM4, LL_TIM_CHANNEL_CH3);
  LL_TIM_SetTriggerOutput(TIM4, LL_TIM_TRGO_OC2REF);
  LL_TIM_DisableMasterSlaveMode(TIM4);
  LL_TIM_OC_DisablePreload(TIM4, LL_TIM_CHANNEL_CH1);
  LL_AHB1_GRP1_EnableClock(LL_AHB1_GRP1_PERIPH_GPIOB);
  /**TIM4 GPIO Configuration
  PB6   ------> TIM4_CH1
  */
  GPIO_InitStruct.Pin = HSYNC_Pin;
  GPIO_InitStruct.Mode = LL_GPIO_MODE_ALTERNATE;
  GPIO_InitStruct.Speed = LL_GPIO_SPEED_FREQ_HIGH;
  GPIO_InitStruct.OutputType = LL_GPIO_OUTPUT_PUSHPULL;
  GPIO_InitStruct.Pull = LL_GPIO_PULL_NO;
  GPIO_InitStruct.Alternate = LL_GPIO_AF_2;
  LL_GPIO_Init(HSYNC_GPIO_Port, &GPIO_InitStruct);

}

static void MX_USART1_UART_Init(void)
{

  LL_USART_InitTypeDef USART_InitStruct = {0};

  LL_GPIO_InitTypeDef GPIO_InitStruct = {0};

  /* Peripheral clock enable */
  LL_APB2_GRP1_EnableClock(LL_APB2_GRP1_PERIPH_USART1);

  LL_AHB1_GRP1_EnableClock(LL_AHB1_GRP1_PERIPH_GPIOA);
  /**USART1 GPIO Configuration
  PA9   ------> USART1_TX
  PA10   ------> USART1_RX
  */
  GPIO_InitStruct.Pin = LL_GPIO_PIN_9|LL_GPIO_PIN_10;
  GPIO_InitStruct.Mode = LL_GPIO_MODE_ALTERNATE;
  GPIO_InitStruct.Speed = LL_GPIO_SPEED_FREQ_VERY_HIGH;
  GPIO_InitStruct.OutputType = LL_GPIO_OUTPUT_PUSHPULL;
  GPIO_InitStruct.Pull = LL_GPIO_PULL_NO;
  GPIO_InitStruct.Alternate = LL_GPIO_AF_7;
  LL_GPIO_Init(GPIOA, &GPIO_InitStruct);

  /* USART1 interrupt Init */
  NVIC_SetPriority(USART1_IRQn, NVIC_EncodePriority(NVIC_GetPriorityGrouping(),5, 0));
  NVIC_EnableIRQ(USART1_IRQn);

  USART_InitStruct.BaudRate = 115200;
  USART_InitStruct.DataWidth = LL_USART_DATAWIDTH_8B;
  USART_InitStruct.StopBits = LL_USART_STOPBITS_1;
  USART_InitStruct.Parity = LL_USART_PARITY_NONE;
  USART_InitStruct.TransferDirection = LL_USART_DIRECTION_TX_RX;
  USART_InitStruct.HardwareFlowControl = LL_USART_HWCONTROL_NONE;
  USART_InitStruct.OverSampling = LL_USART_OVERSAMPLING_16;
  LL_USART_Init(USART1, &USART_InitStruct);
  LL_USART_ConfigAsyncMode(USART1);
  LL_USART_Enable(USART1);

}

static void MX_DMA_Init(void)
{

  /* Init with LL driver */
  /* DMA controller clock enable */
  LL_AHB1_GRP1_EnableClock(LL_AHB1_GRP1_PERIPH_DMA2);
  LL_AHB1_GRP1_EnableClock(LL_AHB1_GRP1_PERIPH_DMA1);

  /* DMA interrupt init */
  /* DMA1_Stream5_IRQn interrupt configuration */
  NVIC_SetPriority(DMA1_Stream5_IRQn, NVIC_EncodePriority(NVIC_GetPriorityGrouping(),5, 0));
  NVIC_EnableIRQ(DMA1_Stream5_IRQn);
  /* DMA1_Stream6_IRQn interrupt configuration */
  NVIC_SetPriority(DMA1_Stream6_IRQn, NVIC_EncodePriority(NVIC_GetPriorityGrouping(),5, 0));
  NVIC_EnableIRQ(DMA1_Stream6_IRQn);
  /* DMA2_Stream3_IRQn interrupt configuration */
  HAL_NVIC_SetPriority(DMA2_Stream3_IRQn, 5, 0);
  HAL_NVIC_EnableIRQ(DMA2_Stream3_IRQn);
  /* DMA2_Stream5_IRQn interrupt configuration */
  NVIC_SetPriority(DMA2_Stream5_IRQn, NVIC_EncodePriority(NVIC_GetPriorityGrouping(),5, 0));
  NVIC_EnableIRQ(DMA2_Stream5_IRQn);
  /* DMA2_Stream6_IRQn interrupt configuration */
  HAL_NVIC_SetPriority(DMA2_Stream6_IRQn, 5, 0);
  HAL_NVIC_EnableIRQ(DMA2_Stream6_IRQn);

}

static void MX_GPIO_Init(void)
{
  LL_EXTI_InitTypeDef EXTI_InitStruct = {0};
  LL_GPIO_InitTypeDef GPIO_InitStruct = {0};

  /* GPIO Ports Clock Enable */
  LL_AHB1_GRP1_EnableClock(LL_AHB1_GRP1_PERIPH_GPIOE);
  LL_AHB1_GRP1_EnableClock(LL_AHB1_GRP1_PERIPH_GPIOC);
  LL_AHB1_GRP1_EnableClock(LL_AHB1_GRP1_PERIPH_GPIOH);
  LL_AHB1_GRP1_EnableClock(LL_AHB1_GRP1_PERIPH_GPIOA);
  LL_AHB1_GRP1_EnableClock(LL_AHB1_GRP1_PERIPH_GPIOB);
  LL_AHB1_GRP1_EnableClock(LL_AHB1_GRP1_PERIPH_GPIOD);

  /**/
  LL_GPIO_SetOutputPin(LED_D2_GPIO_Port, LED_D2_Pin);

  /**/
  LL_GPIO_SetOutputPin(FLASH_CS_GPIO_Port, FLASH_CS_Pin);

  /**/
  LL_GPIO_ResetOutputPin(GPIOE, R0_Pin|R1_Pin|R2_Pin|G0_Pin
                          |G1_Pin|G2_Pin|B0_Pin|B1_Pin);

  /**/
  LL_GPIO_ResetOutputPin(VSYNC_GPIO_Port, VSYNC_Pin);

  /**/
  LL_SYSCFG_SetEXTISource(LL_SYSCFG_EXTI_PORTE, LL_SYSCFG_EXTI_LINE3);

  /**/
  LL_SYSCFG_SetEXTISource(LL_SYSCFG_EXTI_PORTE, LL_SYSCFG_EXTI_LINE4);

  /**/
  LL_SYSCFG_SetEXTISource(LL_SYSCFG_EXTI_PORTC, LL_SYSCFG_EXTI_LINE6);

  /**/
  EXTI_InitStruct.Line_0_31 = LL_EXTI_LINE_3;
  EXTI_InitStruct.LineCommand = ENABLE;
  EXTI_InitStruct.Mode = LL_EXTI_MODE_IT;
  EXTI_InitStruct.Trigger = LL_EXTI_TRIGGER_RISING_FALLING;
  LL_EXTI_Init(&EXTI_InitStruct);

  /**/
  EXTI_InitStruct.Line_0_31 = LL_EXTI_LINE_4;
  EXTI_InitStruct.LineCommand = ENABLE;
  EXTI_InitStruct.Mode = LL_EXTI_MODE_IT;
  EXTI_InitStruct.Trigger = LL_EXTI_TRIGGER_RISING_FALLING;
  LL_EXTI_Init(&EXTI_InitStruct);

  /**/
  EXTI_InitStruct.Line_0_31 = LL_EXTI_LINE_6;
  EXTI_InitStruct.LineCommand = ENABLE;
  EXTI_InitStruct.Mode = LL_EXTI_MODE_IT;
  EXTI_InitStruct.Trigger = LL_EXTI_TRIGGER_FALLING;
  LL_EXTI_Init(&EXTI_InitStruct);

  /**/
  LL_GPIO_SetPinPull(KEY1_GPIO_Port, KEY1_Pin, LL_GPIO_PULL_UP);

  /**/
  LL_GPIO_SetPinPull(KEY0_GPIO_Port, KEY0_Pin, LL_GPIO_PULL_UP);

  /**/
  LL_GPIO_SetPinPull(PS2_CK_GPIO_Port, PS2_CK_Pin, LL_GPIO_PULL_UP);

  /**/
  LL_GPIO_SetPinMode(KEY1_GPIO_Port, KEY1_Pin, LL_GPIO_MODE_INPUT);

  /**/
  LL_GPIO_SetPinMode(KEY0_GPIO_Port, KEY0_Pin, LL_GPIO_MODE_INPUT);

  /**/
  LL_GPIO_SetPinMode(PS2_CK_GPIO_Port, PS2_CK_Pin, LL_GPIO_MODE_INPUT);

  /**/
  GPIO_InitStruct.Pin = BOGO_CARDDETECT_Pin;
  GPIO_InitStruct.Mode = LL_GPIO_MODE_INPUT;
  GPIO_InitStruct.Pull = LL_GPIO_PULL_DOWN;
  LL_GPIO_Init(BOGO_CARDDETECT_GPIO_Port, &GPIO_InitStruct);

  /**/
  GPIO_InitStruct.Pin = LED_D2_Pin;
  GPIO_InitStruct.Mode = LL_GPIO_MODE_OUTPUT;
  GPIO_InitStruct.Speed = LL_GPIO_SPEED_FREQ_LOW;
  GPIO_InitStruct.OutputType = LL_GPIO_OUTPUT_OPENDRAIN;
  GPIO_InitStruct.Pull = LL_GPIO_PULL_NO;
  LL_GPIO_Init(LED_D2_GPIO_Port, &GPIO_InitStruct);

  /**/
  GPIO_InitStruct.Pin = FLASH_CS_Pin;
  GPIO_InitStruct.Mode = LL_GPIO_MODE_OUTPUT;
  GPIO_InitStruct.Speed = LL_GPIO_SPEED_FREQ_VERY_HIGH;
  GPIO_InitStruct.OutputType = LL_GPIO_OUTPUT_PUSHPULL;
  GPIO_InitStruct.Pull = LL_GPIO_PULL_NO;
  LL_GPIO_Init(FLASH_CS_GPIO_Port, &GPIO_InitStruct);

  /**/
  GPIO_InitStruct.Pin = R0_Pin|R1_Pin|R2_Pin|G0_Pin
                          |G1_Pin|G2_Pin|B0_Pin|B1_Pin;
  GPIO_InitStruct.Mode = LL_GPIO_MODE_OUTPUT;
  GPIO_InitStruct.Speed = LL_GPIO_SPEED_FREQ_VERY_HIGH;
  GPIO_InitStruct.OutputType = LL_GPIO_OUTPUT_PUSHPULL;
  GPIO_InitStruct.Pull = LL_GPIO_PULL_NO;
  LL_GPIO_Init(GPIOE, &GPIO_InitStruct);

  /**/
  GPIO_InitStruct.Pin = PS2_DATA_Pin;
  GPIO_InitStruct.Mode = LL_GPIO_MODE_INPUT;
  GPIO_InitStruct.Pull = LL_GPIO_PULL_UP;
  LL_GPIO_Init(PS2_DATA_GPIO_Port, &GPIO_InitStruct);

  /**/
  GPIO_InitStruct.Pin = VSYNC_Pin;
  GPIO_InitStruct.Mode = LL_GPIO_MODE_OUTPUT;
  GPIO_InitStruct.Speed = LL_GPIO_SPEED_FREQ_HIGH;
  GPIO_InitStruct.OutputType = LL_GPIO_OUTPUT_PUSHPULL;
  GPIO_InitStruct.Pull = LL_GPIO_PULL_NO;
  LL_GPIO_Init(VSYNC_GPIO_Port, &GPIO_InitStruct);

  /* EXTI interrupt init*/
  NVIC_SetPriority(EXTI3_IRQn, NVIC_EncodePriority(NVIC_GetPriorityGrouping(),5, 0));
  NVIC_EnableIRQ(EXTI3_IRQn);
  NVIC_SetPriority(EXTI4_IRQn, NVIC_EncodePriority(NVIC_GetPriorityGrouping(),5, 0));
  NVIC_EnableIRQ(EXTI4_IRQn);
  NVIC_SetPriority(EXTI9_5_IRQn, NVIC_EncodePriority(NVIC_GetPriorityGrouping(),5, 0));
  NVIC_EnableIRQ(EXTI9_5_IRQn);

}

/* USER CODE BEGIN 4 */

//====================================================

//this is made a function simply for tidiness, and locals lifetime
void __startWorkerTasks ( void )
{
	//kick off the monitor thread, which handles the user interactions
	{
	osThreadStaticDef(taskMonitor, thrdfxnMonitorTask, osPriorityNormal, 0, COUNTOF(g_tbMonitor), g_tbMonitor, &g_tcbMonitor);
	g_thMonitor = osThreadCreate(osThread(taskMonitor), NULL);
	}
}

//====================================================
//miscellaneous hooks of our creation

//in this logic, we prefer USART1 over USBCDC
#if HAVE_UART1
#define PREFER_USART1 1
#elif HAVE_USBCDC
#define PREFER_USBCDC 1
#endif

#if PREFER_USBCDC

//well-discplined serial clients will assert DTR, and we
//can use that as an indication that a client application
//opened the port.
//NOTE:  These lines are often also set to an initial state
//by the host's driver, so do not consider these to be
//exclusively an indication of a client connecting.  Hosts
//usually will deassert these signals when this device
//enumerates.  Lastly, there is no guarantee that a client
//will assert DTR, so it's not 100% guarantee, just a pretty
//good indicator.
//NOTE:  we are in an ISR at this time
void USBCDC_DTR ( int bAssert )
{
	Monitor_ClientConnect ( bAssert );
}

//(unneeded)
//void USBCDC_RTS ( int bAssert ) { }
#endif

#if PREFER_USBCDC
void USBCDC_DataAvailable ( void )
#elif PREFER_USART1
void UART1_DataAvailable ( void )
#endif
#if PREFER_USBCDC || PREFER_USART1
{
	//this notification is required because our Monitor is implemented with the
	//non-blocking command interface, so we need to know when to wake and bake.
	Monitor_DAV();
}
#endif

#if PREFER_USBCDC
void USBCDC_TransmitEmpty ( void )
#elif PREFER_USART1
void UART1_TransmitEmpty ( void )
#endif
#if PREFER_USBCDC || PREFER_USART1
{
	//we don't really need this, but here's how you do it
	Monitor_TBMT();
}
#endif

//====================================================
//FreeRTOS hooks

void vApplicationStackOverflowHook(xTaskHandle xTask, signed char *pcTaskName)
{
	/* Run time stack overflow checking is performed if
	configCHECK_FOR_STACK_OVERFLOW is defined to 1 or 2. This hook function is
	called if a stack overflow is detected. */
	volatile int i = 0;
	(void)i;
}

void vApplicationMallocFailedHook(void)
{
	/* vApplicationMallocFailedHook() will only be called if
	configUSE_MALLOC_FAILED_HOOK is set to 1 in FreeRTOSConfig.h. It is a hook
	function that will get called if a call to pvPortMalloc() fails.
	pvPortMalloc() is called internally by the kernel whenever a task, queue,
	timer or semaphore is created. It is also called by various parts of the
	demo application. If heap_1.c or heap_2.c are used, then the size of the
	heap available to pvPortMalloc() is defined by configTOTAL_HEAP_SIZE in
	FreeRTOSConfig.h, and the xPortGetFreeHeapSize() API function can be used
	to query the size of free heap space that remains (although it does not
	provide information on how the remaining heap might be fragmented). */
	volatile int i = 0;
	(void)i;
}

//====================================================
//EXTI support

void EXTI_3_ISR ( void )
{
	//KEY1
}

void EXTI_4_ISR ( void )
{
	//KEY0
}

void EXTI_6_ISR ( void )
{
	//PS2_CK
}

//SPI1 Init for W25Q16 Flash 2MB; 50 MHz max, so we divide down to 42 MHz

/* USER CODE END 4 */

void StartDefaultTask(void const * argument)
{
  /* init code for USB_DEVICE */
  MX_USB_DEVICE_Init();

  /* init code for LWIP */
  MX_LWIP_Init();
  /* USER CODE BEGIN 5 */

	//

	// Write to Backup SRAM with 32-Bit Data
#if 0
	for (uint32_t i = 0x0; i < 0x100; i += 4) {
		*(__IO uint32_t*)(BKPSRAM_BASE + i) = i;
	}
#endif

#if 0
	// Check the written Data
	for (uint32_t i = 0x0; i < 0x100; i += 4) {
		if ((*(__IO uint32_t*)(BKPSRAM_BASE + i)) != i){
			Error_Handler();
		}
	}
#endif

	//crank up serial ports
#if HAVE_UART1
	UART1_Init();	//UART1, alternative monitor
#endif
#if HAVE_USBCDC
	USBCDC_Init();	//CDC == monitor
#endif

	//bind the interfaces to the relevant devices
	//these 'HAVE_xxx' macros are in the preprocessor defs of the project
#if PREFER_USBCDC
	//we'll prefer the USB CDC if we've defined support for both
	g_pMonitorIOIf = &g_pifCDC;		//monitor is on USB CDC
#elif PREFER_USART1
	g_pMonitorIOIf = &g_pifUART1;	//monitor is on UART1
#endif

#if 0
	{
		/*
		NOTE: There are some goofy defines in fatfs.h/.c in generated code:

		uint8_t retSD;    // Return value for SD
		char SDPath[4];   // SD logical drive path
		FATFS SDFatFS;    // File system object for SD logical drive
		FIL SDFile;       // File object for SD

		The last two are not used anywhere in the 'middleware', so feel free
		to ignore them and define your own.  if you use 'data sections' in the
		linker config, they will be discarded.

		The first two are unfortunately used, so you have to work harder to
		make them go away.  But... they are only used in MX_FATFS_Init(), which
		in turn only does FATFS_LinkDriver(), so you could do some magicry to
		make those go away, too.
		*/

		//Register the file system object to the FatFs module
		//note; the SDFatFS and SDPath are in fatfs.h (why?)
		SDPath[0] = '0';
		SDPath[1] = ':';
		SDPath[2] = '\0';
		FRESULT fr = f_mount ( &SDFatFS, (TCHAR const*)SDPath, 1 );
		if ( fr != FR_OK )
		{
			//will be FR_NOT_READY if no disk
			//FatFs Initialization Error
			Error_Handler();
		}
		else
		{
			//Open the text file object with read access
			//note; the SDFile is in fatfs.h (why?)
			if ( f_open ( &SDFile, "dummy.txt", FA_READ ) != FR_OK)
			{
				//'dummy.txt' file Open for read Error
				Error_Handler();
			}
			else
			{
				//Read data from the text file
				uint32_t bytesread;
				uint8_t rtext[100];
				fr = f_read ( &SDFile, rtext, sizeof(rtext), (void *)&bytesread );
				if ( ( bytesread == 0 ) || ( fr != FR_OK ) )
				{
					//'dummy.txt' file Read or EOF Error
					Error_Handler();
				}
				else
				{
					//YYY something
				}

				/* Close the open text file */
				f_close ( &SDFile );
			}

			//Open the text file object with write access
			//note; the SDFile is in fatfs.h (why?)
			if ( f_open ( &SDFile, "dummy2.txt", FA_CREATE_ALWAYS | FA_WRITE | FA_READ ) != FR_OK)
			{
				//'dummy2.txt' file Open for write Error
				Error_Handler();
			}
			else
			{
				//Write data to the text file
				uint32_t byteswritten;
				static char szText[] = "lalalililulu\n";
				fr = f_write ( &SDFile, szText, strlen(szText), (void *)&byteswritten );
				if ( ( byteswritten == 0 ) || ( fr != FR_OK ) )
				{
					//'dummy.txt' file Write error or disk full
					Error_Handler();
				}
				else
				{
					//YYY something
				}

				/* Close the open text file */
				f_close ( &SDFile );
			}

			f_mount ( NULL, (TCHAR const*)"", 0 );
		}
	}
#endif

	{
		uint32_t start, end;
		start = getCyCnt();
		//if ( 0 != dsptest_fft() )
		//{
		//	Error_Handler();
		//}
		end = getCyCnt();
		volatile uint32_t nDur = end - start;
		volatile int i = 0;
	}

	//set up the video subsystem
	Video_Initialize();

/*
	//Infinite loop
	for(;;)
	{
		_ledToggleD2();
		_ledToggleD3();
		osDelay(500);
	}
*/

	//light some lamps on a countdown
	LightLamp ( 1000, &g_lltD2, _ledOnD2 );
	//LightLamp ( 2000, &g_lltD3, _ledOnD3 );

	//start up worker threads
	__startWorkerTasks();

	//================================================
	//temporary test crap
	{
	volatile size_t nPushed;

#if PREFER_USART1 && defined(DEBUG)
	//the uart1 monitor is for my debugging convenience, but it doesn't have a
	//'client connected' event, so squirt out a string to make it obvious we
	//are live
	g_pifUART1._transmitCompletely ( &g_pifUART1, "Hi, there!\r\n> ", -1, 1000 );
#endif

	(void) nPushed;
	nPushed = 0;	//(just for breakpoint)
	}

#ifdef DEBUG
	//alas, the LWIP and ETH discard the thread id's they create
	//we will use carnal knowledge of their thread names, and the xTaskGetHandle api
	g_thTCP = xTaskGetHandle( TCPIP_THREAD_NAME );
	g_thETH = xTaskGetHandle( "EthIf" );
#endif

	//================================================
	//continue running this task
	//This task, the 'default' task, was generated by the tool, and it's easier
	//to just keep it than to fight the tool to destroy it (though some of that
	//fighting can be made a little easier if it was dynamically allocated,
	//then just exited).  We repurpose it after init to handle the lamps and
	//periodically sample performance data (useful for tuning pre-release).

	//Infinite loop
	uint32_t msWait = 1000;
	for(;;)
	{
		//wait on various task notifications
		uint32_t ulNotificationValue;
		BaseType_t xResult = xTaskNotifyWait( pdFALSE,	//Don't clear bits on entry.
				0xffffffff,	//Clear all bits on exit.
				&ulNotificationValue,	//Stores the notified value.
				pdMS_TO_TICKS(msWait) );
		if( xResult == pdPASS )
		{
			//the lights have changed
			if ( ulNotificationValue & TNB_LIGHTSCHANGED )
			{
				//YYY could do something, but we don't need to
			}
		}
		else	//timeout on wait
		{
			//YYY could do things to do on periodic idle timeout
		}

#ifdef DEBUG
		//these are to tune the freertos heap size; if we have a heap
#if USE_FREERTOS_HEAP_IMPL
		g_nHeapFree = xPortGetFreeHeapSize();
		g_nMinEverHeapFree = xPortGetMinimumEverFreeHeapSize();
#else
		g_nMinEverHeapFree = (char*)platform_get_last_free_ram( 0 ) - (char*)platform_get_first_free_ram( 0 );
#endif
#if HAVE_UART1
		g_nMaxUART1TxQueue = UART1_txbuff_max();
		g_nMaxUART1RxQueue = UART1_rxbuff_max();
#endif
#if HAVE_USBCDC
		g_nMaxCDCTxQueue = CDC_txbuff_max();
		g_nMaxCDCRxQueue = CDC_rxbuff_max();
#endif
		//free stack space measurements
		g_nMinStackFreeDefault = uxTaskGetStackHighWaterMark ( defaultTaskHandle );
		g_nMinStackFreeMonitor = uxTaskGetStackHighWaterMark ( g_thMonitor );
		g_nMinStackFreeTCP = uxTaskGetStackHighWaterMark ( g_thTCP );
		g_nMinStackFreeETH = uxTaskGetStackHighWaterMark ( g_thETH );
		//XXX others
#endif

		//turn out the lights, the party's over
		uint32_t now = HAL_GetTick();
		uint32_t remMin = 0xffffffff;	//nothing yet
		ProcessLightOffTime ( now, &remMin, &g_lltD2, _ledOffD2 );
		//ProcessLightOffTime ( now, &remMin, &g_lltD3, _ledOffD3 );

		//don't wait longer than 3 sec
		if ( remMin > 3000 )
			remMin = 3000;

		msWait = remMin;
	}

  /* USER CODE END 5 */
}

 /**
  * @brief  Period elapsed callback in non blocking mode
  * @note   This function is called  when TIM12 interrupt took place, inside
  * HAL_TIM_IRQHandler(). It makes a direct call to HAL_IncTick() to increment
  * a global variable "uwTick" used as application time base.
  * @param  htim : TIM handle
  * @retval None
  */
void HAL_TIM_PeriodElapsedCallback(TIM_HandleTypeDef *htim)
{
  if (htim->Instance == TIM12) {
    HAL_IncTick();
  }
}

void Error_Handler(void)
{
  /* USER CODE BEGIN Error_Handler_Debug */
  /* User can add his own implementation to report the HAL error return state */
	volatile int i = 0;
	(void)i;
  /* USER CODE END Error_Handler_Debug */
}

#ifdef  USE_FULL_ASSERT
/**
  * @brief  Reports the name of the source file and the source line number
  *         where the assert_param error has occurred.
  * @param  file: pointer to the source file name
  * @param  line: assert_param error line source number
  * @retval None
  */
void assert_failed(uint8_t *file, uint32_t line)
{
  /* USER CODE BEGIN 6 */
  /* User can add his own implementation to report the file name and line number,
     tex: printf("Wrong parameters value: file %s on line %d\r\n", file, line) */
	volatile int i = 0;
	(void)i;
  /* USER CODE END 6 */
}
#endif /* USE_FULL_ASSERT */

/************************ (C) COPYRIGHT STMicroelectronics *****END OF FILE****/

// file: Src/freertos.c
/* USER CODE BEGIN Header */
/**
  ******************************************************************************
  * File Name          : freertos.c
  * Description        : Code for freertos applications
  ******************************************************************************
  * @attention
  *
  * <h2><center>&copy; Copyright (c) 2020 STMicroelectronics.
  * All rights reserved.</center></h2>
  *
  * This software component is licensed by ST under Ultimate Liberty license
  * SLA0044, the "License"; You may not use this file except in compliance with
  * the License. You may obtain a copy of the License at:
  *                             www.st.com/SLA0044
  *
  ******************************************************************************
  */
/* USER CODE END Header */

#include "FreeRTOS.h"
#include "task.h"
#include "main.h"

/* GetIdleTaskMemory prototype (linked to static allocation support) */
void vApplicationGetIdleTaskMemory( StaticTask_t **ppxIdleTaskTCBBuffer, StackType_t **ppxIdleTaskStackBuffer, uint32_t *pulIdleTaskStackSize );

/* Hook prototypes */
void vApplicationStackOverflowHook(xTaskHandle xTask, signed char *pcTaskName);
void vApplicationMallocFailedHook(void);

/* USER CODE BEGIN 4 */
__weak void vApplicationStackOverflowHook(xTaskHandle xTask, signed char *pcTaskName)
{
   /* Run time stack overflow checking is performed if
   configCHECK_FOR_STACK_OVERFLOW is defined to 1 or 2. This hook function is
   called if a stack overflow is detected. */
}
/* USER CODE END 4 */

/* USER CODE BEGIN 5 */
__weak void vApplicationMallocFailedHook(void)
{
   /* vApplicationMallocFailedHook() will only be called if
   configUSE_MALLOC_FAILED_HOOK is set to 1 in FreeRTOSConfig.h. It is a hook
   function that will get called if a call to pvPortMalloc() fails.
   pvPortMalloc() is called internally by the kernel whenever a task, queue,
   timer or semaphore is created. It is also called by various parts of the
   demo application. If heap_1.c or heap_2.c are used, then the size of the
   heap available to pvPortMalloc() is defined by configTOTAL_HEAP_SIZE in
   FreeRTOSConfig.h, and the xPortGetFreeHeapSize() API function can be used
   to query the size of free heap space that remains (although it does not
   provide information on how the remaining heap might be fragmented). */
}
/* USER CODE END 5 */

/* USER CODE BEGIN GET_IDLE_TASK_MEMORY */
static StaticTask_t xIdleTaskTCBBuffer;
static StackType_t xIdleStack[configMINIMAL_STACK_SIZE];

void vApplicationGetIdleTaskMemory( StaticTask_t **ppxIdleTaskTCBBuffer, StackType_t **ppxIdleTaskStackBuffer, uint32_t *pulIdleTaskStackSize )
{
  *ppxIdleTaskTCBBuffer = &xIdleTaskTCBBuffer;
  *ppxIdleTaskStackBuffer = &xIdleStack[0];
  *pulIdleTaskStackSize = configMINIMAL_STACK_SIZE;
  /* place for user code */
}
/* USER CODE END GET_IDLE_TASK_MEMORY */

/************************ (C) COPYRIGHT STMicroelectronics *****END OF FILE****/
